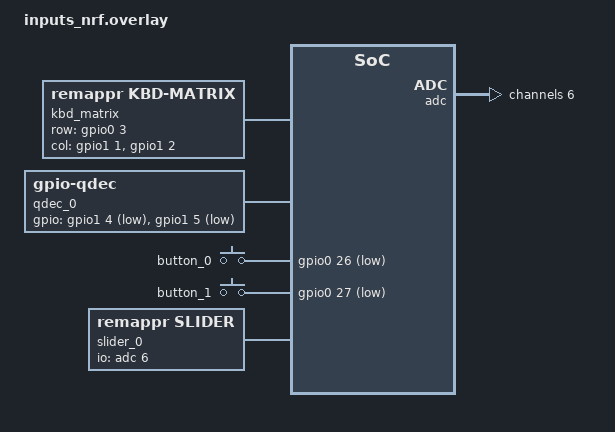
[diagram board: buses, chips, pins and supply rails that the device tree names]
/*
 * Inputs nRF — Remappr shield (generated by remappr).
 *
 * Drop this directory into a remappr-firmware checkout under
 * boards/shields/inputs_nrf/ and build with -D<app>_SHIELD=inputs_nrf. Verify the
 * row/col GPIO specs against your wiring — remappr derives the matrix
 * cells from physical key position, not the electrical matrix.
 *
 * SPDX-License-Identifier: Apache-2.0
 */

#include <zephyr/dt-bindings/input/input-event-codes.h>
#include <zephyr/dt-bindings/input/keymap.h>
#include <dt-bindings/remappr/keys.h>
#include <dt-bindings/remappr/layout.h>
#include <remappr/keymap-tokens.dtsi>
#include <remappr/behavior-tokens.dtsi>
#include <zephyr/dt-bindings/adc/adc.h>
#include <zephyr/dt-bindings/adc/nrf-saadc.h>

/ {
	kbd_matrix: kbd-matrix {
		compatible = "remappr,kbd-matrix";
		diode-direction = "col2row";
		row-gpios =
			<&gpio0 3 (GPIO_ACTIVE_HIGH | GPIO_PULL_DOWN)>;
		col-gpios =
			<&gpio1 1 GPIO_ACTIVE_HIGH>,
			<&gpio1 2 GPIO_ACTIVE_HIGH>;

		keymap {
			compatible = "input-keymap";
			keymap = <
				MATRIX_KEY(0, 0, REMAPPR_KB_POS_BASE + 0) MATRIX_KEY(0, 1, REMAPPR_KB_POS_BASE + 1)
			>;
			row-size = <1>;
			col-size = <2>;
		};
	};

	remappr_keymap: remappr-keymap {
		compatible = "remappr,keymap";
		scan = <&kbd_matrix>;
		columns = <2>;
		rows = <2>;
		max-layers = <4>;
		placement = <
				KEY(&x 0 &y 0) KEY(&x 1 &y 0)
		>;
		layer_0 {
			compatible = "remappr,keymap-layer";
			index = <0>;
			actions = <
				&key 0x04 &key 0x05
			>;
		};
	};
};

/ {
	qdec_0: qdec_0 {
		compatible = "gpio-qdec";
		gpios = <&gpio1 4 (GPIO_ACTIVE_LOW | GPIO_PULL_UP)>, <&gpio1 5 (GPIO_ACTIVE_LOW | GPIO_PULL_UP)>;
		steps-per-period = <4>;
		zephyr,axis = <INPUT_REL_WHEEL>;
		sample-time-us = <1000>;
		idle-timeout-ms = <100>;
	};
};

/ {
	remappr_buttons {
		compatible = "gpio-keys";
		button_0 {
			gpios = <&gpio0 26 (GPIO_ACTIVE_LOW | GPIO_PULL_UP)>;
			zephyr,code = <INPUT_KEY_F13>;
		};
		button_1 {
			gpios = <&gpio0 27 (GPIO_ACTIVE_LOW | GPIO_PULL_UP)>;
			zephyr,code = <INPUT_KEY_ENTER>;
		};
	};
};

/ {
	/* One engine position per button, after the matrix keys'. */
	button_0_key {
		compatible = "remappr,extra-input";
		input-code = <INPUT_KEY_F13>;
		rect = <0 125 150 100>;
	};
	button_1_key {
		compatible = "remappr,extra-input";
		input-code = <INPUT_KEY_ENTER>;
		rect = <200 125 100 100>;
		rot = <1500>;
	};
};

/ {
	slider_0: slider_0 {
		compatible = "remappr,slider";
		io-channels = <&adc 6>;
		function = "rgb-brightness";
		deadband = <3>;
		poll-ms = <30>;
	};
};

&adc {
	status = "okay";
	#address-cells = <1>;
	#size-cells = <0>;

	channel@6 {
		reg = <6>;
		zephyr,gain = "ADC_GAIN_1_6";
		zephyr,reference = "ADC_REF_INTERNAL";
		zephyr,acquisition-time = <ADC_ACQ_TIME_DEFAULT>;
		zephyr,input-positive = <NRF_SAADC_AIN6>;
		zephyr,resolution = <12>;
	};
};
